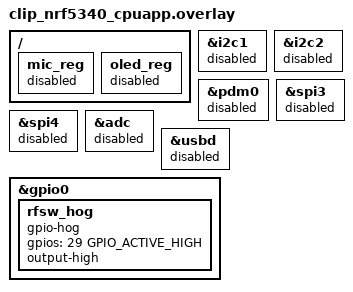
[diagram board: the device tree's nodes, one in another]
/*
 * Copyright (c) 2024 Seeed Studio
 *
 * SPDX-License-Identifier: LicenseRef-Nordic-5-Clause
 */

/* Disable power regulators not needed for radio test */

/ {
	mic_reg {
		status = "disabled";
	};
	oled_reg {
		status = "disabled";
	};
};

/* Disable unused peripherals */

&i2c1 {
	status = "disabled";
};

&i2c2 {
	status = "disabled";
};

&pdm0 {
	status = "disabled";
};

&spi3 {
	status = "disabled";
};

&spi4 {
	status = "disabled";
};

&adc {
	status = "disabled";
};

&usbd {
	status = "disabled";
};

/* RF switch: must be HIGH for WiFi RF path */
&gpio0 {
	rfsw_hog {
		gpio-hog;
		gpios = <29 GPIO_ACTIVE_HIGH>;
		output-high;
	};
};
